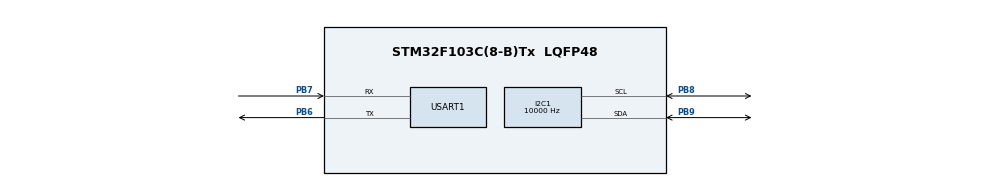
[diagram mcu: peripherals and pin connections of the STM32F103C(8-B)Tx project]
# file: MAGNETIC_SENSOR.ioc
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Dma.I2C1_RX.0.Direction=DMA_PERIPH_TO_MEMORY
Dma.I2C1_RX.0.Instance=DMA1_Channel7
Dma.I2C1_RX.0.MemDataAlignment=DMA_MDATAALIGN_WORD
Dma.I2C1_RX.0.MemInc=DMA_MINC_ENABLE
Dma.I2C1_RX.0.Mode=DMA_CIRCULAR
Dma.I2C1_RX.0.PeriphDataAlignment=DMA_PDATAALIGN_BYTE
Dma.I2C1_RX.0.PeriphInc=DMA_PINC_DISABLE
Dma.I2C1_RX.0.Priority=DMA_PRIORITY_LOW
Dma.Request0=I2C1_RX
I2C1.ClockSpeed=10000
Mcu.Family=STM32F1
Mcu.Name=STM32F103C(8-B)Tx
Mcu.Package=LQFP48
NVIC.DMA1_Channel7_IRQn=true\:0\:0\:false\:false\:true\:false\:true\:true
NVIC.I2C1_ER_IRQn=true\:1\:0\:true\:false\:true\:true\:true\:true
NVIC.I2C1_EV_IRQn=true\:1\:0\:true\:false\:true\:true\:true\:true
NVIC.PriorityGroup=NVIC_PRIORITYGROUP_4
PA13.Mode=Serial_Wire
PA13.Signal=SYS_JTMS-SWDIO
PA14.Mode=Serial_Wire
PA14.Signal=SYS_JTCK-SWCLK
PB6.Mode=Asynchronous
PB6.Signal=USART1_TX
PB7.Mode=Asynchronous
PB7.Signal=USART1_RX
PB8.Mode=I2C
PB8.Signal=I2C1_SCL
PB9.Mode=I2C
PB9.Signal=I2C1_SDA
ProjectManager.HeapSize=0x200
ProjectManager.StackSize=0x400
ProjectManager.TargetToolchain=STM32CubeIDE
RCC.APB1Freq_Value=8000000
RCC.APB2Freq_Value=8000000
USART1.VirtualMode=VM_ASYNC
board=custom

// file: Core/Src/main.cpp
/* USER CODE BEGIN Header */
/**
  ******************************************************************************
  * @file           : main.c
  * @brief          : Main program body
  ******************************************************************************
  * @attention
  *
  * Copyright (c) 2022 STMicroelectronics.
  * All rights reserved.
  *
  * This software is licensed under terms that can be found in the LICENSE file
  * in the root directory of this software component.
  * If no LICENSE file comes with this software, it is provided AS-IS.
  *
  ******************************************************************************
  */
/* USER CODE END Header */
#include "main.h"

/* USER CODE BEGIN Includes */
#include "string.h"
#include "stdio.h"
#include "magnetic_sensor.hpp"
/* USER CODE END Includes */

/* USER CODE BEGIN PTD */
uint8_t AS5600_ADDR = 0x36 << 1;
uint8_t	RAWANG_H	= 0x0C;
uint8_t RAWANG_L	= 0x0D;
uint8_t ANGLE_H		= 0x0E;
uint8_t ANGLE_L		= 0x0F;
uint8_t DMA_I2C_DATA[2];
uint8_t buf[12];
/* USER CODE END PTD */

I2C_HandleTypeDef hi2c1;
DMA_HandleTypeDef hdma_i2c1_rx;

UART_HandleTypeDef huart1;

void SystemClock_Config(void);
static void MX_GPIO_Init(void);
static void MX_DMA_Init(void);
static void MX_I2C1_Init(void);
static void MX_USART1_UART_Init(void);

/* USER CODE BEGIN 0 */

//void HAL_I2C_MasterRxCpltCallback(I2C_HandleTypeDef *hi2c)
//{
//  // RX Done .. Do Something!
//	int Data = (DMA_I2C_DATA[1]|(DMA_I2C_DATA[0] << 8));
//	sprintf((char*)buf,"%d\r\n",Data);
//}

/* USER CODE END 0 */

int main(void)
{

  /* MCU Configuration--------------------------------------------------------*/

  /* Reset of all peripherals, Initializes the Flash interface and the Systick. */
  HAL_Init();

  /* USER CODE BEGIN Init */
  AS5600 as5600(hi2c1, huart1);
  /* USER CODE END Init */

  /* Configure the system clock */
  SystemClock_Config();

  /* Initialize all configured peripherals */
  MX_GPIO_Init();
  MX_DMA_Init();
  MX_I2C1_Init();
  MX_USART1_UART_Init();
  /* USER CODE BEGIN 2 */

//  HAL_I2C_Master_Receive_DMA(&hi2c1, AS5600_ADDR, DMA_I2C_DATA, 18);
//  HAL_I2C_Mem_Read_DMA(&hi2c1, AS5600_ADDR, RAWANG_H, 1, &DMA_I2C_DATA[0], 100);
//  HAL_I2C_Mem_Read_DMA(&hi2c1, AS5600_ADDR, RAWANG_L, 1, &DMA_I2C_DATA[1], 100);
  /* USER CODE END 2 */

  /* Infinite loop */
  /* USER CODE BEGIN WHILE */
  while (1)
  {
	as5600.GetStatus();
	as5600.GetAngle();
//	  int Data = 100;
//	  sprintf((char*)buf,"%d\r\n",Data);
//	  HAL_UART_Transmit(&huart1, buf,  strlen((char*)buf), HAL_MAX_DELAY);
	HAL_Delay(100);

//	int Data = (DMA_I2C_DATA[1]|(DMA_I2C_DATA[0] << 8));
//	uint8_t recv;
//	if ((recv = HAL_I2C_Mem_Read_DMA(&hi2c1, AS5600_ADDR,RAWANG_L, I2C_MEMADD_SIZE_8BIT, &DMA_I2C_DATA[1], 1)) == HAL_OK){
//		sprintf((char*)buf,"%d\r\n",DMA_I2C_DATA[1]);
//		HAL_UART_Transmit(&huart1, buf,  strlen((char*)buf), HAL_MAX_DELAY);
//		HAL_Delay(100);
//	}
//	else{
//		int Data = 100;
//		sprintf((char*)buf,"%d\r\n",Data);
//		HAL_UART_Transmit(&huart1, buf,  strlen((char*)buf), HAL_MAX_DELAY);
//		HAL_Delay(100);
//	}
    /* USER CODE END WHILE */

  }
}

void SystemClock_Config(void)
{
  RCC_OscInitTypeDef RCC_OscInitStruct = {0};
  RCC_ClkInitTypeDef RCC_ClkInitStruct = {0};

  /** Initializes the RCC Oscillators according to the specified parameters
  * in the RCC_OscInitTypeDef structure.
  */
  RCC_OscInitStruct.OscillatorType = RCC_OSCILLATORTYPE_HSI;
  RCC_OscInitStruct.HSIState = RCC_HSI_ON;
  RCC_OscInitStruct.HSICalibrationValue = RCC_HSICALIBRATION_DEFAULT;
  RCC_OscInitStruct.PLL.PLLState = RCC_PLL_NONE;
  if (HAL_RCC_OscConfig(&RCC_OscInitStruct) != HAL_OK)
  {
    Error_Handler();
  }

  /** Initializes the CPU, AHB and APB buses clocks
  */
  RCC_ClkInitStruct.ClockType = RCC_CLOCKTYPE_HCLK|RCC_CLOCKTYPE_SYSCLK
                              |RCC_CLOCKTYPE_PCLK1|RCC_CLOCKTYPE_PCLK2;
  RCC_ClkInitStruct.SYSCLKSource = RCC_SYSCLKSOURCE_HSI;
  RCC_ClkInitStruct.AHBCLKDivider = RCC_SYSCLK_DIV1;
  RCC_ClkInitStruct.APB1CLKDivider = RCC_HCLK_DIV1;
  RCC_ClkInitStruct.APB2CLKDivider = RCC_HCLK_DIV1;

  if (HAL_RCC_ClockConfig(&RCC_ClkInitStruct, FLASH_LATENCY_0) != HAL_OK)
  {
    Error_Handler();
  }
}

static void MX_I2C1_Init(void)
{

  hi2c1.Instance = I2C1;
  hi2c1.Init.ClockSpeed = 10000;
  hi2c1.Init.DutyCycle = I2C_DUTYCYCLE_2;
  hi2c1.Init.OwnAddress1 = 0;
  hi2c1.Init.AddressingMode = I2C_ADDRESSINGMODE_7BIT;
  hi2c1.Init.DualAddressMode = I2C_DUALADDRESS_DISABLE;
  hi2c1.Init.OwnAddress2 = 0;
  hi2c1.Init.GeneralCallMode = I2C_GENERALCALL_DISABLE;
  hi2c1.Init.NoStretchMode = I2C_NOSTRETCH_DISABLE;
  if (HAL_I2C_Init(&hi2c1) != HAL_OK)
  {
    Error_Handler();
  }

}

static void MX_USART1_UART_Init(void)
{

  huart1.Instance = USART1;
  huart1.Init.BaudRate = 115200;
  huart1.Init.WordLength = UART_WORDLENGTH_8B;
  huart1.Init.StopBits = UART_STOPBITS_1;
  huart1.Init.Parity = UART_PARITY_NONE;
  huart1.Init.Mode = UART_MODE_TX_RX;
  huart1.Init.HwFlowCtl = UART_HWCONTROL_NONE;
  huart1.Init.OverSampling = UART_OVERSAMPLING_16;
  if (HAL_UART_Init(&huart1) != HAL_OK)
  {
    Error_Handler();
  }

}

static void MX_DMA_Init(void)
{

  /* DMA controller clock enable */
  __HAL_RCC_DMA1_CLK_ENABLE();

  /* DMA interrupt init */
  /* DMA1_Channel7_IRQn interrupt configuration */
  HAL_NVIC_SetPriority(DMA1_Channel7_IRQn, 0, 0);
  HAL_NVIC_EnableIRQ(DMA1_Channel7_IRQn);

}

static void MX_GPIO_Init(void)
{

  /* GPIO Ports Clock Enable */
  __HAL_RCC_GPIOA_CLK_ENABLE();
  __HAL_RCC_GPIOB_CLK_ENABLE();

}

void Error_Handler(void)
{
  __disable_irq();
  while (1)
  {
  }
}
